AUTOSAR XML (schema 4.0)
package /ECU_Project
  ecu configuration EngineECU_Config: ecu=EngineECU, ecu-extract=EngineSystem  # Engine Control Unit Configuration
    module config Can
    module config NvM
    module config Com
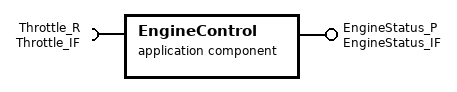
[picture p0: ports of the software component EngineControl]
  application sw component type EngineControl  # Engine Control Application Component
    provide port EngineStatus_P: provided-interface=EngineStatus_IF
    require port Throttle_R: required-interface=Throttle_IF
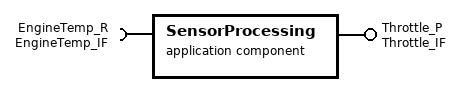
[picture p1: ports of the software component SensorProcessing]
  application sw component type SensorProcessing  # Sensor Data Processing Component
    provide port Throttle_P: provided-interface=Throttle_IF
    require port EngineTemp_R: required-interface=EngineTemp_IF
  sender receiver interface EngineStatus_IF
    data EngineRPM: type=uint16
    data EngineTemp: type=sint16
  sender receiver interface Throttle_IF
    data ThrottlePosition: type=uint8
  sender receiver interface EngineTemp_IF
    data CoolantTemp: type=sint16
  app type uint8: category=VALUE
  app type uint16: category=VALUE
  app type sint16: category=VALUE
  system mapping EngineSystemMapping
    swc to ecu mapping EngineControlMapping: component=EngineControl, ecu=EngineECU_Config
    swc to ecu mapping SensorProcessingMapping: component=SensorProcessing, ecu=EngineECU_Config
    connections:
      connect SensorProcessing.Throttle_P -> EngineControl.Throttle_R
